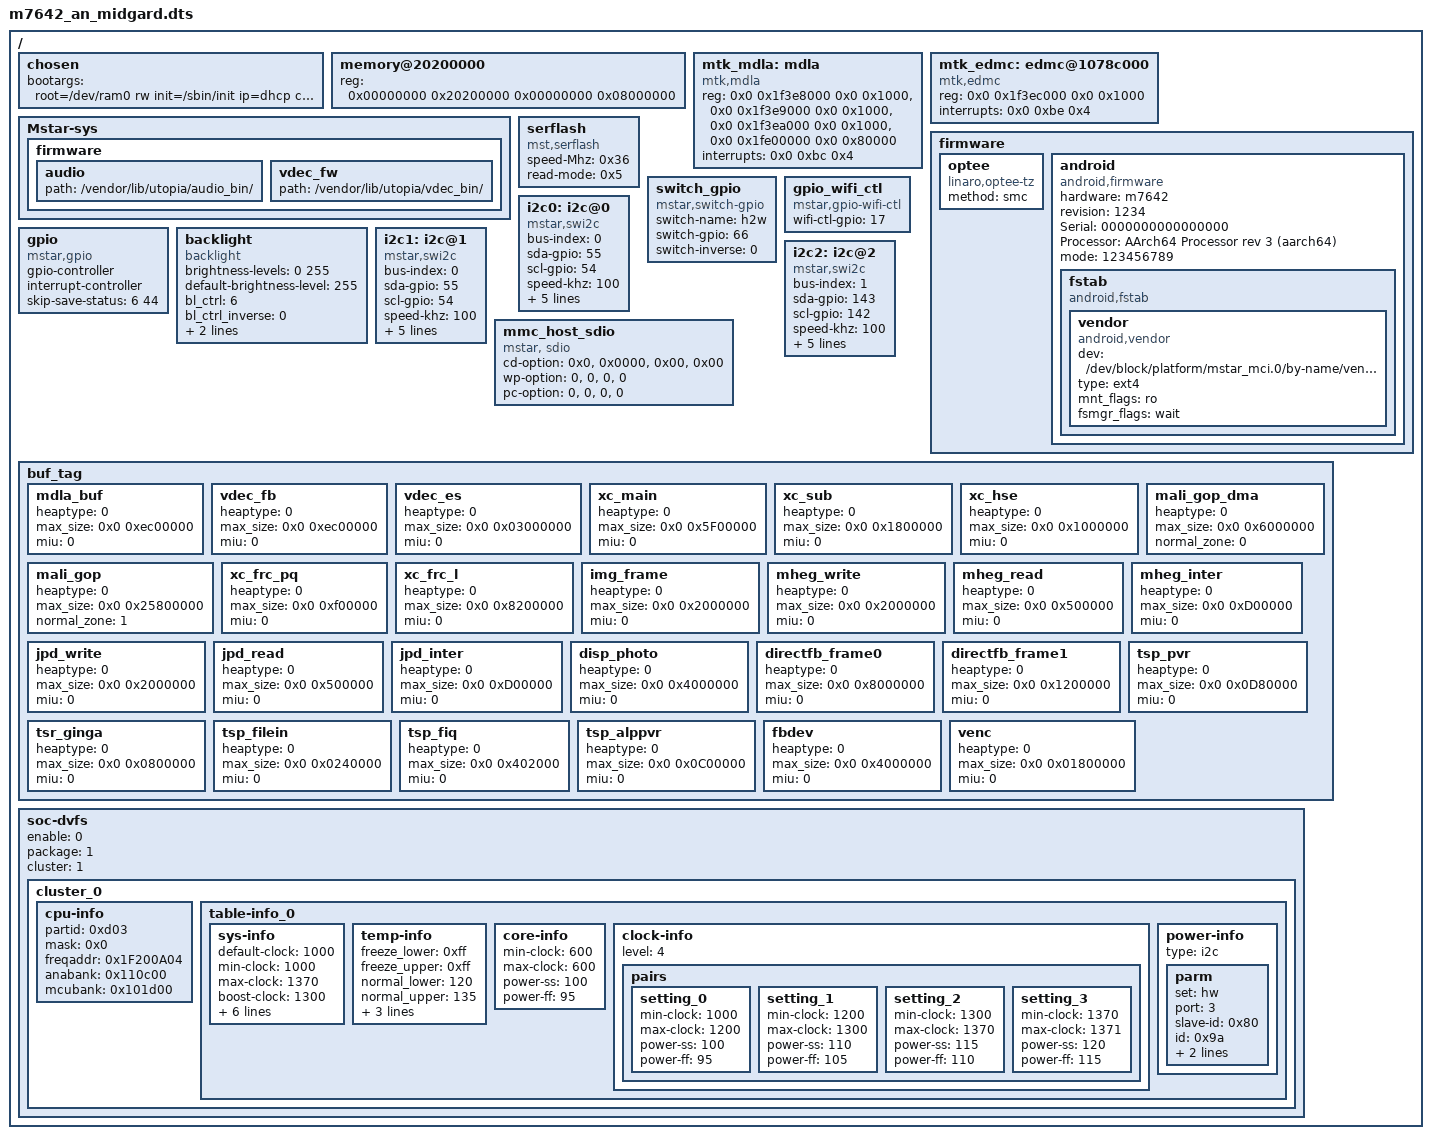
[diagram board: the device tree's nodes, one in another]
/*
 * ARM Ltd.
 *
 * ARMv8 Foundation model DTS
 */

/dts-v1/;
#include "../../../../../drivers/mstar2/hal/m7642/gpio/mhal_gpio_reg.h"
#include "m7642.dtsi"

/ {
    /* rdinit=/sbin/init */
	chosen {
         bootargs = "root=/dev/ram0 rw init=/sbin/init ip=dhcp console=ttyS0,38400,LX_MEM=0x03000000";
        };

	memory@20200000 {
		device_type = "memory";
		reg = <0x00000000 0x20200000 0x00000000 0x08000000>;
	};

	mtk_mdla: mdla {
		  compatible = "mtk,mdla";
		  reg =   <0x0 0x1f3e8000 0x0 0x1000>,
		      <0x0 0x1f3e9000 0x0 0x1000>,
		      <0x0 0x1f3ea000 0x0 0x1000>,
		      <0x0 0x1fe00000 0x0 0x80000>;
		  interrupts = <0x0 0xbc 0x4>;
	};

	mtk_edmc: edmc@1078c000 {
		  compatible = "mtk,edmc";
		  reg = <0x0 0x1f3ec000 0x0 0x1000>;
		  interrupts = <0x0 0xbe 0x4>;
	};

	Mstar-sys {
		firmware {
			audio {
				path = "/vendor/lib/utopia/audio_bin/";
			};
			vdec_fw {
				path = "/vendor/lib/utopia/vdec_bin/";
			};
		};
	};

	firmware {

                optee {
                        compatible = "linaro,optee-tz";
                        method = "smc";
                };

		android {
			compatible = "android,firmware";
			hardware = "m7642";
			revision = "1234";
			Serial = "0000000000000000";
			Processor = "AArch64 Processor rev 3 (aarch64)";
			mode = "123456789";

                        fstab {
				compatible = "android,fstab";

                                vendor {
					compatible = "android,vendor";
					dev = "/dev/block/platform/mstar_mci.0/by-name/vendor";
					type = "ext4";
					mnt_flags = "ro";
					fsmgr_flags = "wait";
				};
			};
		};
	};

	serflash {
		compatible = "mst,serflash";
		speed-Mhz = <0x36>;
		read-mode = <0x5>;
	};

	switch_gpio {
		compatible = "mstar,switch-gpio";
		switch-name = "h2w";
		switch-gpio = <66>;
		switch-inverse = <0>;
	};

	gpio: gpio {
		compatible = "mstar,gpio";
		gpio-controller;
		#gpio-cells = <1>;
		interrupt-controller;
		skip-save-status = <6 44>;
		#interrupt-cells = <2>; /* cell name GPIO_PAD, trigger-type*/
	};

	gpio_wifi_ctl {
		compatible = "mstar,gpio-wifi-ctl";
		wifi-ctl-gpio = <17>;
	};

	backlight {
		compatible = "backlight";
		brightness-levels = <0 255>;
		default-brightness-level = <255>;
		bl_ctrl = <6>;
		bl_ctrl_inverse = <0>;
		vcc_gpio = <44>;
		vcc_gpio_invert = <0>;
		/* led-pwm-control-support; */
		/* led-pwm-control-channel = <0>; */
		/* led-pwm-control-resume-period = <0xb71a>; */
		/* led-pwm-control-resume-duty = <0xb71a>; */
		/* led-pwm-control-resume-div = <0xff>; */
		/* led-pwm-control-resume-polarity = <0>; */
		/* led-pwm-control-suspend-period = <0xb71a>; */
		/* led-pwm-control-suspend-duty = <0xb71a>; */
		/* led-pwm-control-suspend-div = <0xff>; */
		/* led-pwm-control-suspend-polarity = <0>; */
	};

	i2c0: i2c@0 {
		compatible = "mstar,swi2c";
		bus-index = <0>;
		sda-gpio = <55>;
		scl-gpio = <54>;
		speed-khz = <100>;
		def-delay = <100>;
		retries = <5>;
		status = "okay";
		iic-mode = <0>;
		hw-port = <0>;
		pad-mux = <0>;
	};

	i2c1: i2c@1 {
		compatible = "mstar,swi2c";
		bus-index = <0>;
		sda-gpio = <55>;
		scl-gpio = <54>;
		speed-khz = <100>;
		def-delay = <100>;
		retries = <5>;
		status = "okay";
		iic-mode = <1>;
		hw-port = <3>;
		pad-mux = <25>;
	};

	i2c2: i2c@2 {
		compatible = "mstar,swi2c";
		bus-index = <1>;
		sda-gpio = <143>;
		scl-gpio = <142>;
		speed-khz = <100>;
		def-delay = <100>;
		retries = <5>;
		status = "okay";
		iic-mode = <0>;
		hw-port = <0>;
		pad-mux = <0>;
	};

	mmc_host_sdio {
		compatible = "mstar, sdio";
		cd-option = <0x0>,<0x0000>,<0x00>,<0x00>;
		wp-option = <0>,<0>,<0>,<0>;
		pc-option =  <0>,<0>,<0>,<0>;
	};

	buf_tag {
	/* heaptype: HEAP_TYPE_IOMMU = 0, HEAP_TYPE_CMA= 1,  HEAP_TYPE_NON_MMA = 2*/
	/* miutype:  UMA_OR_MIU0 = 0, MIU_1 = 1 */
		mdla_buf {
			heaptype = <0>;
			max_size = <0x0 0xec00000>;
			miu = <0>;
		};
		vdec_fb {
			heaptype = <0>;
			max_size = <0x0 0xec00000>;
			miu = <0>;
		};
		vdec_es {
			heaptype = <0>;
			max_size = <0x0 0x03000000>;
			miu = <0>;
		};
		xc_main {
			heaptype = <0>;
			max_size = <0x0 0x5F00000>;
			miu = <0>;
		};
		xc_sub {
			heaptype = <0>;
			max_size = <0x0 0x1800000>;
			miu = <0>;
		};
		xc_hse {
			heaptype = <0>;
			max_size = <0x0 0x1000000>;
			miu = <0>;
		};
		mali_gop_dma {
			heaptype = <0>;
			max_size = <0x0 0x6000000>;
			normal_zone = <0>;
		};
		mali_gop {
			heaptype = <0>;
			max_size = <0x0 0x25800000>;
			normal_zone = <1>;
		};
		xc_frc_pq {
			heaptype = <0>;
			max_size = <0x0 0xf00000>;
			miu = <0>;
		};
		xc_frc_l {
			heaptype = <0>;
			max_size = <0x0 0x8200000>;
			miu = <0>;
		};
		img_frame {
			heaptype = <0>;
			max_size = <0x0 0x2000000>;
			miu = <0>;
		};
		mheg_write {
			heaptype = <0>;
			max_size = <0x0 0x2000000>;
			miu = <0>;
		};
		mheg_read {
			heaptype = <0>;
			max_size = <0x0 0x500000>;
			miu = <0>;
		};
		mheg_inter {
			heaptype = <0>;
			max_size = <0x0 0xD00000>;
			miu = <0>;
		};
		jpd_write {
			heaptype = <0>;
			max_size = <0x0 0x2000000>;
			miu = <0>;
		};
		jpd_read {
			heaptype = <0>;
			max_size = <0x0 0x500000>;
			miu = <0>;
		};
		jpd_inter {
			heaptype = <0>;
			max_size = <0x0 0xD00000>;
			miu = <0>;
		};
		disp_photo {
			heaptype = <0>;
			max_size = <0x0 0x4000000>;
			miu = <0>;
		};
		directfb_frame0 {
			heaptype = <0>;
			max_size = <0x0 0x8000000>;
			miu = <0>;
		};
		directfb_frame1 {
			heaptype = <0>;
			max_size = <0x0 0x1200000>;
			miu = <0>;
		};
		tsp_pvr {
			heaptype = <0>;
			max_size = <0x0 0x0D80000>;
			miu = <0>;
		};
        tsr_ginga {
             heaptype = <0>;
             max_size = <0x0 0x0800000>;
             miu = <0>;
         };
		tsp_filein {
			heaptype = <0>;
			max_size = <0x0 0x0240000>;
			miu = <0>;
		};
		tsp_fiq {
			heaptype = <0>;
			max_size = <0x0 0x402000>;
			miu = <0>;
		};
		tsp_alppvr {
			heaptype = <0>;
			max_size = <0x0 0x0C00000>;
			miu = <0>;
		};
		fbdev {
			heaptype = <0>;
			max_size = <0x0 0x4000000>;
			miu = <0>;
		};
		venc {
			heaptype = <0>;
			max_size = <0x0 0x01800000>;
			miu = <0>;
                };
	};

	soc-dvfs {
		enable =  <0>;
		package = <1>;
		cluster = <1>;
		cluster_0 {
			cpu-info {
				partid =    <0xd03>;
				mask   =    <0x0>;
				freqaddr =  <0x1F200A04>;
				anabank =   <0x110c00>;
				mcubank =   <0x101d00>;
			};
			table-info_0 {
				sys-info {
					default-clock = <1000>;
					min-clock =     <1000>;
					max-clock =     <1370>;
					boost-clock =   <1300>;
					antutu-clock =  <1370>;
					protect-clock = <800>;
					default-cpu =   <100>;
					default-core =  <100>;
					max-cpu =       <120>;
					min-cpu =       <90>;
				};
				temp-info {
					freeze_lower =  <0xff>;
					freeze_upper =  <0xff>;
					normal_lower =  <120>;
					normal_upper =  <135>;
					reset =         <150>;
					power-ss     =  <90>;
					power-ff     =  <90>;
				};
				core-info {
					min-clock =     <600>;
					max-clock =     <600>;
					power-ss =      <100>;
					power-ff =      <95>;
				};
				clock-info {
					level = <4>;
					pairs {
						setting_0 {
							min-clock = <1000>;
							max-clock = <1200>;
							power-ss =  <100>;
							power-ff =  <95>;
						};
						setting_1 {
							min-clock = <1200>;
							max-clock = <1300>;
							power-ss =  <110>;
							power-ff =  <105>;
						};
						setting_2 {
							min-clock = <1300>;
							max-clock = <1370>;
							power-ss =  <115>;
							power-ff =  <110>;
						};
						setting_3 {
							min-clock = <1370>;
							max-clock = <1371>;
							power-ss =  <120>;
							power-ff =  <115>;
						};
					};
				};
				power-info {
					type = "i2c";
					parm {
						set =       "hw";
						port =      <3>;
						slave-id =  <0x80>;
						id =        <0x9a>;
						shift =     <1>;
						step =      <3>;
					};
				};
			};
		};
    };
};
